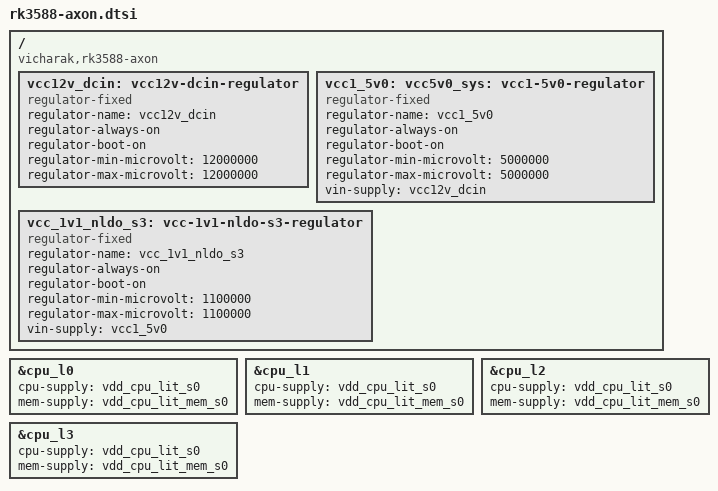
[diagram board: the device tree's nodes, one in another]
// SPDX-License-Identifier: (GPL-2.0+ OR MIT)
/*
 * Copyright (C) 2023 Vicharak Computers LLP
 */

#include "rk3588.dtsi"
#include "rk3588-rk806-single.dtsi"

/ {
	compatible = "vicharak,rk3588-axon", "rockchip,rk3588";

	vcc12v_dcin: vcc12v-dcin-regulator {
		compatible = "regulator-fixed";
		regulator-name = "vcc12v_dcin";
		regulator-always-on;
		regulator-boot-on;
		regulator-min-microvolt = <12000000>;
		regulator-max-microvolt = <12000000>;
	};

	vcc1_5v0: vcc5v0_sys: vcc1-5v0-regulator {
		compatible = "regulator-fixed";
		regulator-name = "vcc1_5v0";
		regulator-always-on;
		regulator-boot-on;
		regulator-min-microvolt = <5000000>;
		regulator-max-microvolt = <5000000>;
		vin-supply = <&vcc12v_dcin>;
	};

	vcc_1v1_nldo_s3: vcc-1v1-nldo-s3-regulator {
		compatible = "regulator-fixed";
		regulator-name = "vcc_1v1_nldo_s3";
		regulator-always-on;
		regulator-boot-on;
		regulator-min-microvolt = <1100000>;
		regulator-max-microvolt = <1100000>;
		vin-supply = <&vcc1_5v0>;
	};
};

&cpu_l0 {
	cpu-supply = <&vdd_cpu_lit_s0>;
	mem-supply = <&vdd_cpu_lit_mem_s0>;
};

&cpu_l1 {
	cpu-supply = <&vdd_cpu_lit_s0>;
	mem-supply = <&vdd_cpu_lit_mem_s0>;
};

&cpu_l2 {
	cpu-supply = <&vdd_cpu_lit_s0>;
	mem-supply = <&vdd_cpu_lit_mem_s0>;
};

&cpu_l3 {
	cpu-supply = <&vdd_cpu_lit_s0>;
	mem-supply = <&vdd_cpu_lit_mem_s0>;
};
